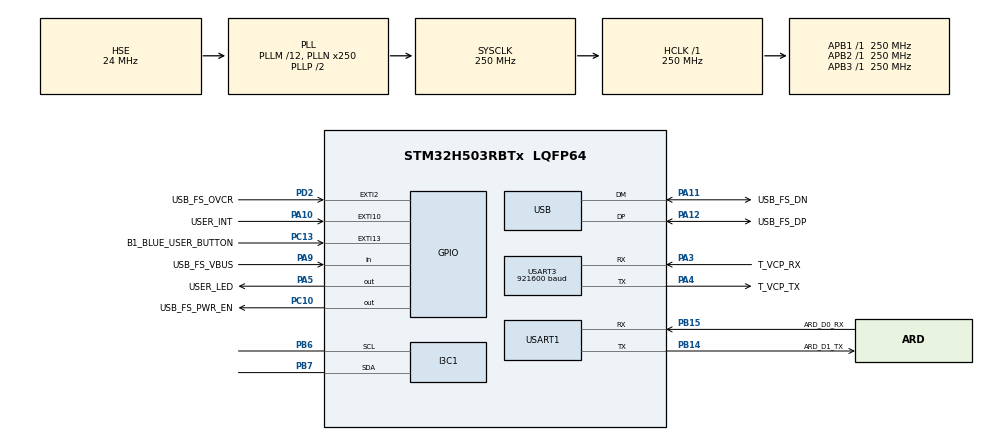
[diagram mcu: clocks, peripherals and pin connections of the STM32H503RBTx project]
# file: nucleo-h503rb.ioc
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GPDMA1.DIRECTION_GPDMACH0=DMA_MEMORY_TO_PERIPH
GPDMA1.IPHANDLE_GPDMACH0-SIMPLEREQUEST_GPDMACH0=__NULL
GPDMA1.REQUEST_GPDMACH0=GPDMA1_REQUEST_USART3_TX
GPDMA1.SRCINC_GPDMACH0=DMA_SINC_INCREMENTED
I3C1.BusFreeDuration=402
I3C1.Register0=0x00774f77
I3C1.Register1=0x103200f8
I3C1.SCLI3CHighDuration=0x4f
I3C1.SCLODLowDuration=0x77
I3C1.SCLPPLowDuration=0x77
I3C1.SDAHoldTime=HAL_I3C_SDA_HOLD_TIME_1_5
I3C1.hexBusFreeDuration=0x32
I3C1.hexBusIdleDuration=0xf8
Mcu.Family=STM32H5
Mcu.Name=STM32H503RBTx
Mcu.Package=LQFP64
NVIC.EXTI10_IRQn=true\:0\:0\:false\:false\:true\:true\:true\:true
NVIC.GPDMA1_Channel0_IRQn=true\:0\:0\:false\:false\:true\:false\:true\:true
NVIC.I3C1_ER_IRQn=true\:0\:0\:false\:false\:true\:true\:true\:true
NVIC.I3C1_EV_IRQn=true\:0\:0\:false\:false\:true\:true\:true\:true
NVIC.PriorityGroup=NVIC_PRIORITYGROUP_4
NVIC.USART3_IRQn=true\:0\:0\:false\:false\:true\:true\:true\:true
PA10.GPIO_Label=USER_INT
PA10.Signal=GPXTI10
PA11.GPIO_Label=USB_FS_DN
PA11.Mode=Device
PA11.Signal=USB_DM
PA12.GPIO_Label=USB_FS_DP
PA12.Mode=Device
PA12.Signal=USB_DP
PA13(JTMS/SWDIO).GPIO_Label=T_SWDIO
PA13(JTMS/SWDIO).Mode=JTAG_4_pins
PA13(JTMS/SWDIO).Signal=DEBUG_JTMS-SWDIO
PA14(JTCK/SWCLK).GPIO_Label=T_SWCLK
PA14(JTCK/SWCLK).Mode=JTAG_4_pins
PA14(JTCK/SWCLK).Signal=DEBUG_JTCK-SWCLK
PA15(JTDI).GPIO_Label=T_JTDI
PA15(JTDI).Mode=JTAG_4_pins
PA15(JTDI).Signal=DEBUG_JTDI
PA3.GPIO_Label=T_VCP_RX
PA3.Mode=Asynchronous
PA3.Signal=USART3_RX
PA4.GPIO_Label=T_VCP_TX
PA4.Mode=Asynchronous
PA4.Signal=USART3_TX
PA5.GPIO_Label=USER_LED
PA5.Signal=GPIO_Output
PA9.GPIO_Label=USB_FS_VBUS
PA9.Signal=GPIO_Input
PB14.GPIO_Label=ARD_D1_TX
PB14.Mode=Asynchronous
PB14.Signal=USART1_TX
PB15.GPIO_Label=ARD_D0_RX
PB15.Mode=Asynchronous
PB15.Signal=USART1_RX
PB3(JTDO/TRACESWO).GPIO_Label=T_SWO
PB3(JTDO/TRACESWO).Mode=JTAG_4_pins
PB3(JTDO/TRACESWO).Signal=DEBUG_JTDO-SWO
PB6.Mode=Controller
PB6.Signal=I3C1_SCL
PB7.Mode=Controller
PB7.Signal=I3C1_SDA
PC10.GPIO_Label=USB_FS_PWR_EN
PC10.Signal=GPIO_Output
PC13.GPIO_Label=B1_BLUE_USER_BUTTON
PC13.Signal=GPXTI13
PC14-OSC32_IN(OSC32_IN).Mode=LSE-External-Oscillator
PC14-OSC32_IN(OSC32_IN).Signal=RCC_OSC32_IN
PC15-OSC32_OUT(OSC32_OUT).Mode=LSE-External-Oscillator
PC15-OSC32_OUT(OSC32_OUT).Signal=RCC_OSC32_OUT
PD2.GPIO_Label=USB_FS_OVCR
PD2.Signal=GPXTI2
PH0-OSC_IN(PH0).Mode=HSE-External-Oscillator
PH0-OSC_IN(PH0).Signal=RCC_OSC_IN
PH1-OSC_OUT(PH1).Mode=HSE-External-Oscillator
PH1-OSC_OUT(PH1).Signal=RCC_OSC_OUT
ProjectManager.HeapSize=0x200
ProjectManager.StackSize=0x1000
ProjectManager.TargetToolchain=EWARM V9.20
RCC.ADCFreq_Value=250000000
RCC.AHBFreq_Value=250000000
RCC.APB1Freq_Value=250000000
RCC.APB1TimFreq_Value=250000000
RCC.APB2Freq_Value=250000000
RCC.APB2TimFreq_Value=250000000
RCC.APB3Freq_Value=250000000
RCC.CSI_VALUE=4000000
RCC.CortexFreq_Value=250000000
RCC.EPOD_VALUE=24000000
RCC.HCLKFreq_Value=250000000
RCC.HSE_VALUE=24000000
RCC.HSI48_VALUE=48000000
RCC.HSIDiv=RCC_HSI_DIV1
RCC.HSI_VALUE=64000000
RCC.LSIRC_VALUE=32000
RCC.PLLM=12
RCC.PLLN=250
RCC.PLLSourceVirtual=RCC_PLL1_SOURCE_HSE
RCC.SYSCLKFreq_VALUE=250000000
RCC.SYSCLKSource=RCC_SYSCLKSOURCE_PLLCLK
RCC.USBFreq_Value=48000000
RCC.VCOOutputFreq_Value=500000000
USART1.VirtualMode=VM_ASYNC
USART3.BaudRate=921600
USART3.VirtualMode=VM_ASYNC
USB.VirtualMode=Device_Only
VP_GPDMA1_VS_GPDMACH0.Mode=SIMPLEREQUEST_GPDMACH0
VP_ICACHE_VS_ICACHE.Mode=DefaultMode
VP_PWR_VS_SECSignals.Mode=Security/Privilege
board=NUCLEO-H503RB

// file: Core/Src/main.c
/* USER CODE BEGIN Header */
/**
  ******************************************************************************
  * @file           : main.c
  * @brief          : Main program body
  ******************************************************************************
  * @attention
  *
  * Copyright (c) 2024 STMicroelectronics.
  * All rights reserved.
  *
  * This software is licensed under terms that can be found in the LICENSE file
  * in the root directory of this software component.
  * If no LICENSE file comes with this software, it is provided AS-IS.
  *
  ******************************************************************************
  */
/* USER CODE END Header */
#include "main.h"
#include "gpdma.h"
#include "i3c.h"
#include "icache.h"
#include "usart.h"
#include "usb.h"
#include "gpio.h"

void SystemClock_Config(void);
/* USER CODE BEGIN PFP */
void lsm6dsv16x_fifo_irq(void);
void lsm6dsv16x_fifo_irq_handler(void);

/* USER CODE END PFP */

/* USER CODE BEGIN 0 */
/* overwrite default interrupt callback */
void HAL_GPIO_EXTI_Rising_Callback(uint16_t GPIO_Pin)
{
  lsm6dsv16x_fifo_irq_handler();
}

/* USER CODE END 0 */

int main(void)
{

  /* MCU Configuration--------------------------------------------------------*/

  /* Reset of all peripherals, Initializes the Flash interface and the Systick. */
  HAL_Init();

  /* Configure the system clock */
  SystemClock_Config();

  /* Initialize all configured peripherals */
  MX_GPIO_Init();
  MX_GPDMA1_Init();
  MX_USART1_UART_Init();
  MX_USART3_UART_Init();
  MX_ICACHE_Init();
  MX_I3C1_Init();
  MX_USB_PCD_Init();

  /* Infinite loop */
  while (1)
  {

    /* USER CODE BEGIN 3 */
    lsm6dsv16x_fifo_irq();
  }
  /* USER CODE END 3 */
}

void SystemClock_Config(void)
{
  RCC_OscInitTypeDef RCC_OscInitStruct = {0};
  RCC_ClkInitTypeDef RCC_ClkInitStruct = {0};

  /** Configure the main internal regulator output voltage
  */
  __HAL_PWR_VOLTAGESCALING_CONFIG(PWR_REGULATOR_VOLTAGE_SCALE0);

  while(!__HAL_PWR_GET_FLAG(PWR_FLAG_VOSRDY)) {}

  /** Initializes the RCC Oscillators according to the specified parameters
  * in the RCC_OscInitTypeDef structure.
  */
  RCC_OscInitStruct.OscillatorType = RCC_OSCILLATORTYPE_HSI48|RCC_OSCILLATORTYPE_HSE;
  RCC_OscInitStruct.HSEState = RCC_HSE_ON;
  RCC_OscInitStruct.HSI48State = RCC_HSI48_ON;
  RCC_OscInitStruct.PLL.PLLState = RCC_PLL_ON;
  RCC_OscInitStruct.PLL.PLLSource = RCC_PLL1_SOURCE_HSE;
  RCC_OscInitStruct.PLL.PLLM = 12;
  RCC_OscInitStruct.PLL.PLLN = 250;
  RCC_OscInitStruct.PLL.PLLP = 2;
  RCC_OscInitStruct.PLL.PLLQ = 2;
  RCC_OscInitStruct.PLL.PLLR = 2;
  RCC_OscInitStruct.PLL.PLLRGE = RCC_PLL1_VCIRANGE_1;
  RCC_OscInitStruct.PLL.PLLVCOSEL = RCC_PLL1_VCORANGE_WIDE;
  RCC_OscInitStruct.PLL.PLLFRACN = 0;
  if (HAL_RCC_OscConfig(&RCC_OscInitStruct) != HAL_OK)
  {
    Error_Handler();
  }

  /** Initializes the CPU, AHB and APB buses clocks
  */
  RCC_ClkInitStruct.ClockType = RCC_CLOCKTYPE_HCLK|RCC_CLOCKTYPE_SYSCLK
                              |RCC_CLOCKTYPE_PCLK1|RCC_CLOCKTYPE_PCLK2
                              |RCC_CLOCKTYPE_PCLK3;
  RCC_ClkInitStruct.SYSCLKSource = RCC_SYSCLKSOURCE_PLLCLK;
  RCC_ClkInitStruct.AHBCLKDivider = RCC_SYSCLK_DIV1;
  RCC_ClkInitStruct.APB1CLKDivider = RCC_HCLK_DIV1;
  RCC_ClkInitStruct.APB2CLKDivider = RCC_HCLK_DIV1;
  RCC_ClkInitStruct.APB3CLKDivider = RCC_HCLK_DIV1;

  if (HAL_RCC_ClockConfig(&RCC_ClkInitStruct, FLASH_LATENCY_5) != HAL_OK)
  {
    Error_Handler();
  }
}

void Error_Handler(void)
{
  __disable_irq();
  while (1)
  {
  }
}
